VERSION ""

NS_ :

BS_:

BU_: Node_Receiver Node_Sender

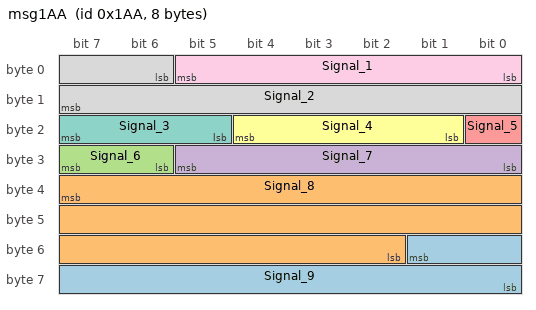
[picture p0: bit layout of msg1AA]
BO_ 426 msg1AA: 8 Node_Sender
 SG_ Signal_9 : 49|10@0+ (1,0) [0|1023] ""  Node_Receiver
 SG_ Signal_8 : 39|22@0+ (1,0) [0|4194303] ""  Node_Receiver
 SG_ Signal_6 : 30|2@1+ (1,0) [0|3] ""  Node_Receiver
 SG_ Signal_7 : 24|6@1+ (1,0) [0|63] ""  Node_Receiver
 SG_ Signal_5 : 16|1@1+ (1,0) [0|1] ""  Node_Receiver
 SG_ Signal_4 : 17|4@1+ (1,0) [0|15] ""  Node_Receiver
 SG_ Signal_3 : 21|3@1+ (1,0) [0|7] ""  Node_Receiver
 SG_ Signal_2 : 6|10@1+ (1,0) [0|1023] ""  Node_Receiver
 SG_ Signal_1 : 0|6@1+ (1,0) [0|63] ""  Node_Receiver

BA_DEF_  "BusType" STRING ;
BA_DEF_DEF_  "BusType" "CAN";
